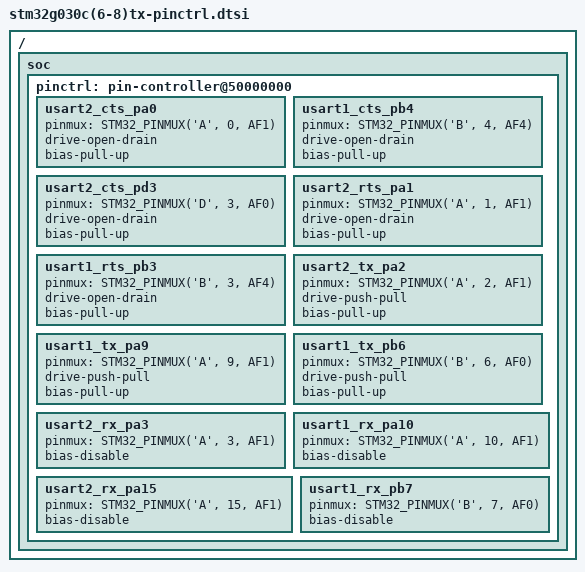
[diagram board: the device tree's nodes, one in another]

/*
 * NOTE: Autogenerated file using stm32_pinctrl_gen.py
 *
 * SPDX-License-Identifier: Apache-2.0
 */

#include <dt-bindings/pinctrl/stm32-pinctrl.h>

/ {
	soc {
		pinctrl: pin-controller@50000000 {
			/* UART_CTS */
			usart2_cts_pa0: usart2_cts_pa0 {
				pinmux = <STM32_PINMUX('A', 0, AF1)>;
				drive-open-drain;
				bias-pull-up;
			};

			usart1_cts_pb4: usart1_cts_pb4 {
				pinmux = <STM32_PINMUX('B', 4, AF4)>;
				drive-open-drain;
				bias-pull-up;
			};

			usart2_cts_pd3: usart2_cts_pd3 {
				pinmux = <STM32_PINMUX('D', 3, AF0)>;
				drive-open-drain;
				bias-pull-up;
			};


			/* UART_RTS */
			usart2_rts_pa1: usart2_rts_pa1 {
				pinmux = <STM32_PINMUX('A', 1, AF1)>;
				drive-open-drain;
				bias-pull-up;
			};

			usart1_rts_pb3: usart1_rts_pb3 {
				pinmux = <STM32_PINMUX('B', 3, AF4)>;
				drive-open-drain;
				bias-pull-up;
			};


			/* UART_TX */
			usart2_tx_pa2: usart2_tx_pa2 {
				pinmux = <STM32_PINMUX('A', 2, AF1)>;
				drive-push-pull;
				bias-pull-up;
			};

			usart1_tx_pa9: usart1_tx_pa9 {
				pinmux = <STM32_PINMUX('A', 9, AF1)>;
				drive-push-pull;
				bias-pull-up;
			};

			usart1_tx_pa9: usart1_tx_pa9 {
				pinmux = <STM32_PINMUX('A', 9, AF1)>;
				drive-push-pull;
				bias-pull-up;
			};

			usart1_tx_pb6: usart1_tx_pb6 {
				pinmux = <STM32_PINMUX('B', 6, AF0)>;
				drive-push-pull;
				bias-pull-up;
			};


			/* UART_RX */
			usart2_rx_pa3: usart2_rx_pa3 {
				pinmux = <STM32_PINMUX('A', 3, AF1)>;
				bias-disable;
			};

			usart1_rx_pa10: usart1_rx_pa10 {
				pinmux = <STM32_PINMUX('A', 10, AF1)>;
				bias-disable;
			};

			usart1_rx_pa10: usart1_rx_pa10 {
				pinmux = <STM32_PINMUX('A', 10, AF1)>;
				bias-disable;
			};

			usart2_rx_pa15: usart2_rx_pa15 {
				pinmux = <STM32_PINMUX('A', 15, AF1)>;
				bias-disable;
			};

			usart1_rx_pb7: usart1_rx_pb7 {
				pinmux = <STM32_PINMUX('B', 7, AF0)>;
				bias-disable;
			};

		};
	};
};
